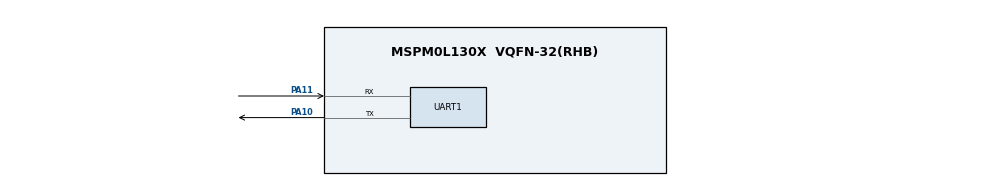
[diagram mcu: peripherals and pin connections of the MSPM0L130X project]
/**
 * @cliArgs --device "MSPM0L130X" --package "VQFN-32(RHB)" --part "Default" --product "mspm0_sdk@1.00.01.03"
 * @versions {"tool":"1.16.1+2960"}
 */

/**
 * Import the modules used in this configuration.
 */
const Board  = scripting.addModule("/ti/driverlib/Board");
const GPIO   = scripting.addModule("/ti/driverlib/GPIO", {}, false);
const GPIO1  = GPIO.addInstance();
const SYSCTL = scripting.addModule("/ti/driverlib/SYSCTL");
const UART   = scripting.addModule("/ti/driverlib/UART", {}, false);
const UART1  = UART.addInstance();

/**
 * Write custom configuration values to the imported modules.
 */
const gate6  = system.clockTree["MFCLKGATE"];
gate6.enable = true;

const gate7  = system.clockTree["MFPCLKGATE"];
gate7.enable = true;


GPIO1.$name                              = "Demo";
GPIO1.associatedPins.create(2);
GPIO1.associatedPins[0].$name            = "LED";
GPIO1.associatedPins[0].assignedPort     = "PORTA";
GPIO1.associatedPins[0].assignedPin      = "14";
GPIO1.associatedPins[0].subOutputPolicy  = "TOGGLE";
GPIO1.associatedPins[0].subChanID        = 1;
GPIO1.associatedPins[1].$name            = "Key";
GPIO1.associatedPins[1].assignedPort     = "PORTA";
GPIO1.associatedPins[1].assignedPin      = "7";
GPIO1.associatedPins[1].internalResistor = "PULL_UP";
GPIO1.associatedPins[1].direction        = "INPUT";
GPIO1.associatedPins[1].interruptEn      = true;
GPIO1.associatedPins[1].polarity         = "RISE_FALL";
GPIO1.associatedPins[1].pubChanID        = 1;

SYSCTL.MFCLKEn     = true;
SYSCTL.MFPCLKEn    = true;
SYSCTL.clockTreeEn = true;

UART1.$name                    = "UART_0";
UART1.uartClkSrc               = "MFCLK";
UART1.targetBaudRate           = 115200;
UART1.enabledInterrupts        = ["RX"];
UART1.peripheral.$assign       = "UART1";
UART1.peripheral.rxPin.$assign = "PA11";
UART1.peripheral.txPin.$assign = "PA10";

/**
 * Pinmux solution for unlocked pins/peripherals. This ensures that minor changes to the automatic solver in a future
 * version of the tool will not impact the pinmux you originally saw.  These lines can be completely deleted in order to
 * re-solve from scratch.
 */
Board.peripheral.$suggestSolution            = "DEBUGSS";
Board.peripheral.swclkPin.$suggestSolution   = "PA20";
Board.peripheral.swdioPin.$suggestSolution   = "PA19";
GPIO1.associatedPins[0].pin.$suggestSolution = "PA14";
GPIO1.associatedPins[1].pin.$suggestSolution = "PA7";
